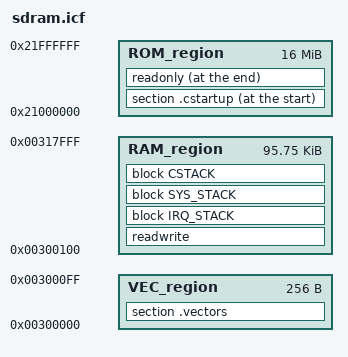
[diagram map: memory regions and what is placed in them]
/*###ICF### Section handled by ICF editor, don't touch! ****/
/*-Editor annotation file-*/
/* IcfEditorFile="$TOOLKIT_DIR$\config\ide\IcfEditor\a_v1_0.xml" */
/*-Specials-*/
define symbol __ICFEDIT_intvec_start__ = 0x300000;
/*-Memory Regions-*/
define symbol __ICFEDIT_region_ROM_start__   = 0x21000000;
define symbol __ICFEDIT_region_ROM_end__     = 0x21ffffff;
define symbol __ICFEDIT_region_RAM_start__   = 0x300100;
define symbol __ICFEDIT_region_RAM_end__     = 0x317fff;
/*-Sizes-*/
define symbol __ICFEDIT_size_vectors__  = 0x100;
define symbol __ICFEDIT_size_cstack__   = 0x500;
define symbol __ICFEDIT_size_sysstack__ = 0x60;
define symbol __ICFEDIT_size_irqstack__ = 0x60;
/**** End of ICF editor section. ###ICF###*/


define memory mem with size = 4G;
define region ROM_region = mem:[from __ICFEDIT_region_ROM_start__   to __ICFEDIT_region_ROM_end__];
define region VEC_region = mem:[from __ICFEDIT_intvec_start__       size __ICFEDIT_size_vectors__];
define region RAM_region = mem:[from __ICFEDIT_region_RAM_start__   to __ICFEDIT_region_RAM_end__];

define block CSTACK    with alignment = 4, size = __ICFEDIT_size_cstack__   { };
define block SYS_STACK with alignment = 4, size = __ICFEDIT_size_sysstack__ { };
define block IRQ_STACK with alignment = 4, size = __ICFEDIT_size_irqstack__ { };

initialize by copy { readwrite };
initialize by copy { section .vectors };
do not initialize  { section .noinit };

place at start of ROM_region { section .cstartup };
place at end of ROM_region { readonly };
place in VEC_region { section .vectors };
place in RAM_region { readwrite  , block IRQ_STACK, block SYS_STACK, block CSTACK};
